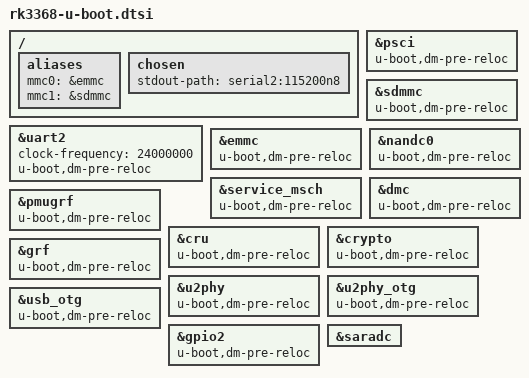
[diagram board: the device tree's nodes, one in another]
/*
 * (C) Copyright 2018 Rockchip Electronics Co., Ltd
 *
 * SPDX-License-Identifier:     GPL-2.0+
 */

/ {
	aliases {
		mmc0 = &emmc;
		mmc1 = &sdmmc;
	};

	chosen {
		stdout-path = "serial2:115200n8";
	};
};

&psci {
	u-boot,dm-pre-reloc;
	status = "okay";
};

&uart2 {
	clock-frequency = <24000000>;
	u-boot,dm-pre-reloc;
};

&sdmmc {
	u-boot,dm-pre-reloc;
	status = "okay";
};

&emmc {
	u-boot,dm-pre-reloc;
	status = "okay";
};

&nandc0 {
	u-boot,dm-pre-reloc;
	status = "okay";
};

&service_msch {
	u-boot,dm-pre-reloc;
};

&dmc {
	u-boot,dm-pre-reloc;
};

&pmugrf {
	u-boot,dm-pre-reloc;
};

&cru {
	u-boot,dm-pre-reloc;
};

&crypto {
	u-boot,dm-pre-reloc;
};

&grf {
	u-boot,dm-pre-reloc;
};

&u2phy {
	u-boot,dm-pre-reloc;
};

&u2phy_otg {
	u-boot,dm-pre-reloc;
};

&usb_otg {
	u-boot,dm-pre-reloc;
};

&gpio2 {
	u-boot,dm-pre-reloc;
};

&saradc {
	u-boot,dm-spl;
	status = "okay";
};
